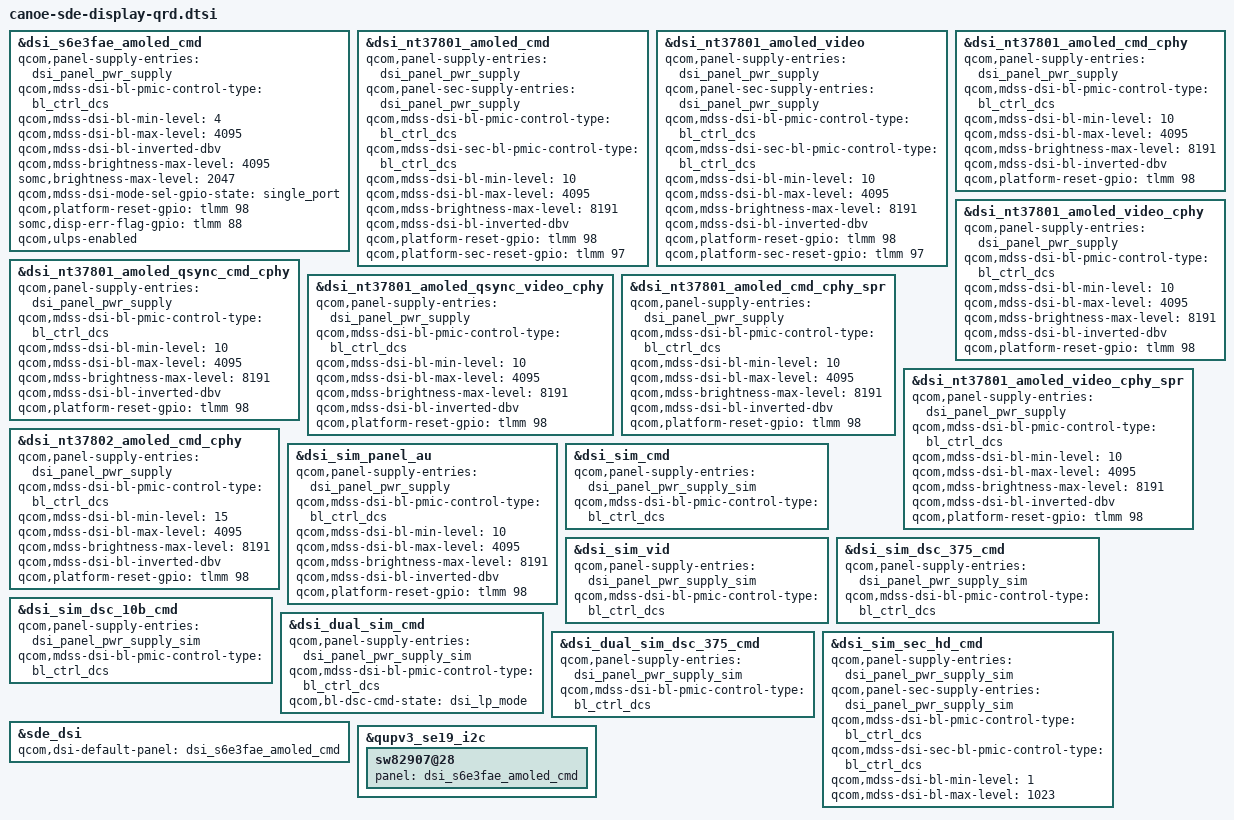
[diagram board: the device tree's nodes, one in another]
// SPDX-License-Identifier: BSD-3-Clause
/*
 * Copyright (c) Qualcomm Technologies, Inc. and/or its subsidiaries.
 */
/*
* Copyright 2025 Sony Corporation
* NOTE: This file has been modified by Sony Corporation
* Modifications are licensed under the License.
*/

#include "canoe-sde-display.dtsi"
#include "canoe-sde-display-hfi.dtsi"

&dsi_s6e3fae_amoled_cmd {
	qcom,panel-supply-entries = <&dsi_panel_pwr_supply>;
	qcom,mdss-dsi-bl-pmic-control-type = "bl_ctrl_dcs";
	qcom,mdss-dsi-bl-min-level = <4>;
	qcom,mdss-dsi-bl-max-level = <4095>;
	qcom,mdss-dsi-bl-inverted-dbv;
	qcom,mdss-brightness-max-level = <4095>;
	somc,brightness-max-level = <2047>;
	qcom,mdss-dsi-mode-sel-gpio-state = "single_port";

	qcom,platform-reset-gpio = <&tlmm 98 0>;
	somc,disp-err-flag-gpio = <&tlmm 88 0>;
	qcom,ulps-enabled;
};

&dsi_nt37801_amoled_cmd {
	qcom,panel-supply-entries = <&dsi_panel_pwr_supply>;
	qcom,panel-sec-supply-entries = <&dsi_panel_pwr_supply>;
	qcom,mdss-dsi-bl-pmic-control-type = "bl_ctrl_dcs";
	qcom,mdss-dsi-sec-bl-pmic-control-type = "bl_ctrl_dcs";
	qcom,mdss-dsi-bl-min-level = <10>;
	qcom,mdss-dsi-bl-max-level = <4095>;
	qcom,mdss-brightness-max-level = <8191>;
	qcom,mdss-dsi-bl-inverted-dbv;
	qcom,platform-reset-gpio = <&tlmm 98 0>;
	qcom,platform-sec-reset-gpio = <&tlmm 97 0>;
};

&dsi_nt37801_amoled_video {
	qcom,panel-supply-entries = <&dsi_panel_pwr_supply>;
	qcom,panel-sec-supply-entries = <&dsi_panel_pwr_supply>;
	qcom,mdss-dsi-bl-pmic-control-type = "bl_ctrl_dcs";
	qcom,mdss-dsi-sec-bl-pmic-control-type = "bl_ctrl_dcs";
	qcom,mdss-dsi-bl-min-level = <10>;
	qcom,mdss-dsi-bl-max-level = <4095>;
	qcom,mdss-brightness-max-level = <8191>;
	qcom,mdss-dsi-bl-inverted-dbv;
	qcom,platform-reset-gpio = <&tlmm 98 0>;
	qcom,platform-sec-reset-gpio = <&tlmm 97 0>;
};

&dsi_nt37801_amoled_cmd_cphy {
	qcom,panel-supply-entries = <&dsi_panel_pwr_supply>;
	qcom,mdss-dsi-bl-pmic-control-type = "bl_ctrl_dcs";
	qcom,mdss-dsi-bl-min-level = <10>;
	qcom,mdss-dsi-bl-max-level = <4095>;
	qcom,mdss-brightness-max-level = <8191>;
	qcom,mdss-dsi-bl-inverted-dbv;
	qcom,platform-reset-gpio = <&tlmm 98 0>;
};

&dsi_nt37801_amoled_video_cphy {
	qcom,panel-supply-entries = <&dsi_panel_pwr_supply>;
	qcom,mdss-dsi-bl-pmic-control-type = "bl_ctrl_dcs";
	qcom,mdss-dsi-bl-min-level = <10>;
	qcom,mdss-dsi-bl-max-level = <4095>;
	qcom,mdss-brightness-max-level = <8191>;
	qcom,mdss-dsi-bl-inverted-dbv;
	qcom,platform-reset-gpio = <&tlmm 98 0>;
};

&dsi_nt37801_amoled_qsync_cmd_cphy {
	qcom,panel-supply-entries = <&dsi_panel_pwr_supply>;
	qcom,mdss-dsi-bl-pmic-control-type = "bl_ctrl_dcs";
	qcom,mdss-dsi-bl-min-level = <10>;
	qcom,mdss-dsi-bl-max-level = <4095>;
	qcom,mdss-brightness-max-level = <8191>;
	qcom,mdss-dsi-bl-inverted-dbv;
	qcom,platform-reset-gpio = <&tlmm 98 0>;
};

&dsi_nt37801_amoled_qsync_video_cphy {
	qcom,panel-supply-entries = <&dsi_panel_pwr_supply>;
	qcom,mdss-dsi-bl-pmic-control-type = "bl_ctrl_dcs";
	qcom,mdss-dsi-bl-min-level = <10>;
	qcom,mdss-dsi-bl-max-level = <4095>;
	qcom,mdss-brightness-max-level = <8191>;
	qcom,mdss-dsi-bl-inverted-dbv;
	qcom,platform-reset-gpio = <&tlmm 98 0>;
};

&dsi_nt37801_amoled_cmd_cphy_spr {
	qcom,panel-supply-entries = <&dsi_panel_pwr_supply>;
	qcom,mdss-dsi-bl-pmic-control-type = "bl_ctrl_dcs";
	qcom,mdss-dsi-bl-min-level = <10>;
	qcom,mdss-dsi-bl-max-level = <4095>;
	qcom,mdss-brightness-max-level = <8191>;
	qcom,mdss-dsi-bl-inverted-dbv;
	qcom,platform-reset-gpio = <&tlmm 98 0>;
};

&dsi_nt37801_amoled_video_cphy_spr {
	qcom,panel-supply-entries = <&dsi_panel_pwr_supply>;
	qcom,mdss-dsi-bl-pmic-control-type = "bl_ctrl_dcs";
	qcom,mdss-dsi-bl-min-level = <10>;
	qcom,mdss-dsi-bl-max-level = <4095>;
	qcom,mdss-brightness-max-level = <8191>;
	qcom,mdss-dsi-bl-inverted-dbv;
	qcom,platform-reset-gpio = <&tlmm 98 0>;
};

&dsi_nt37802_amoled_cmd_cphy {
	qcom,panel-supply-entries = <&dsi_panel_pwr_supply>;
	qcom,mdss-dsi-bl-pmic-control-type = "bl_ctrl_dcs";
	qcom,mdss-dsi-bl-min-level = <15>;
	qcom,mdss-dsi-bl-max-level = <4095>;
	qcom,mdss-brightness-max-level = <8191>;
	qcom,mdss-dsi-bl-inverted-dbv;
	qcom,platform-reset-gpio = <&tlmm 98 0>;
};

&dsi_sim_panel_au {
	qcom,panel-supply-entries = <&dsi_panel_pwr_supply>;
	qcom,mdss-dsi-bl-pmic-control-type = "bl_ctrl_dcs";
	qcom,mdss-dsi-bl-min-level = <10>;
	qcom,mdss-dsi-bl-max-level = <4095>;
	qcom,mdss-brightness-max-level = <8191>;
	qcom,mdss-dsi-bl-inverted-dbv;
	qcom,platform-reset-gpio = <&tlmm 98 0>;
};

&dsi_sim_cmd {
	qcom,panel-supply-entries = <&dsi_panel_pwr_supply_sim>;
	qcom,mdss-dsi-bl-pmic-control-type = "bl_ctrl_dcs";
};

&dsi_sim_vid {
	qcom,panel-supply-entries = <&dsi_panel_pwr_supply_sim>;
	qcom,mdss-dsi-bl-pmic-control-type = "bl_ctrl_dcs";
};

&dsi_sim_dsc_375_cmd {
	qcom,panel-supply-entries = <&dsi_panel_pwr_supply_sim>;
	qcom,mdss-dsi-bl-pmic-control-type = "bl_ctrl_dcs";
};

&dsi_sim_dsc_10b_cmd {
	qcom,panel-supply-entries = <&dsi_panel_pwr_supply_sim>;
	qcom,mdss-dsi-bl-pmic-control-type = "bl_ctrl_dcs";
};

&dsi_dual_sim_cmd {
	qcom,panel-supply-entries = <&dsi_panel_pwr_supply_sim>;
	qcom,mdss-dsi-bl-pmic-control-type = "bl_ctrl_dcs";
	qcom,bl-dsc-cmd-state = "dsi_lp_mode";
};

&dsi_dual_sim_dsc_375_cmd {
	qcom,panel-supply-entries = <&dsi_panel_pwr_supply_sim>;
	qcom,mdss-dsi-bl-pmic-control-type = "bl_ctrl_dcs";
};

&dsi_sim_sec_hd_cmd {
	qcom,panel-supply-entries = <&dsi_panel_pwr_supply_sim>;
	qcom,panel-sec-supply-entries = <&dsi_panel_pwr_supply_sim>;
	qcom,mdss-dsi-bl-pmic-control-type = "bl_ctrl_dcs";
	qcom,mdss-dsi-sec-bl-pmic-control-type = "bl_ctrl_dcs";
	qcom,mdss-dsi-bl-min-level = <1>;
	qcom,mdss-dsi-bl-max-level = <1023>;
};

&sde_dsi {
	qcom,dsi-default-panel = <&dsi_s6e3fae_amoled_cmd>;
};

&qupv3_se19_i2c {
	sw82907@28 {
		panel = <&dsi_s6e3fae_amoled_cmd>;
	};
};
